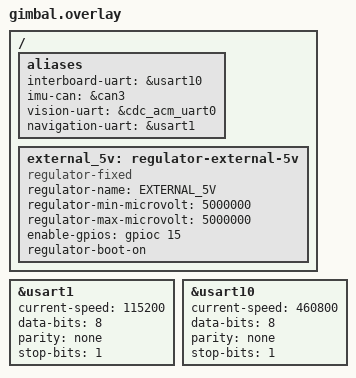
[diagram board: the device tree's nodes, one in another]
#include "common.overlay"
/ {
    aliases {
        interboard-uart = &usart10;
        imu-can = &can3;
        /* Vision link: USB CDC ACM on PA11/PA12 (full speed), declared by the
         * board DTS. No DMA and no separate UART pin is consumed. */
        vision-uart = &cdc_acm_uart0;
        /* Navigation: USART1 PA9/PA10, 115200 8N1. DMA is board-global. */
        navigation-uart = &usart1;
    };
    external_5v: regulator-external-5v {
        compatible = "regulator-fixed";
        regulator-name = "EXTERNAL_5V";
        regulator-min-microvolt = <5000000>;
        regulator-max-microvolt = <5000000>;
        enable-gpios = <&gpioc 15 GPIO_ACTIVE_HIGH>;
        regulator-boot-on;
    };
};
&usart1 {
    status = "okay";
    current-speed = <115200>;
    data-bits = <8>;
    parity = "none";
    stop-bits = "1";
};
&usart10 {
    status = "okay";
    current-speed = <460800>;
    data-bits = <8>;
    parity = "none";
    stop-bits = "1";
};
